# GD32F20x_CL register map
File version: 1.0
CPU: CM3 r2p1, little endian, no MPU, no FPU, 4 interrupt priority bits
Registers are 32-bit, read-write, reset 0x0 unless marked. A register's access mark holds for its fields unless they carry their own. Offsets are from the block's base; [hi:lo] are bit positions; {n}, {i} and the like mark numbered series.

## SDIO — Secure digital input/output interface
Base 0x40018000
0x00 PWRCTL — Power control register
  [1:0] PWRCTL
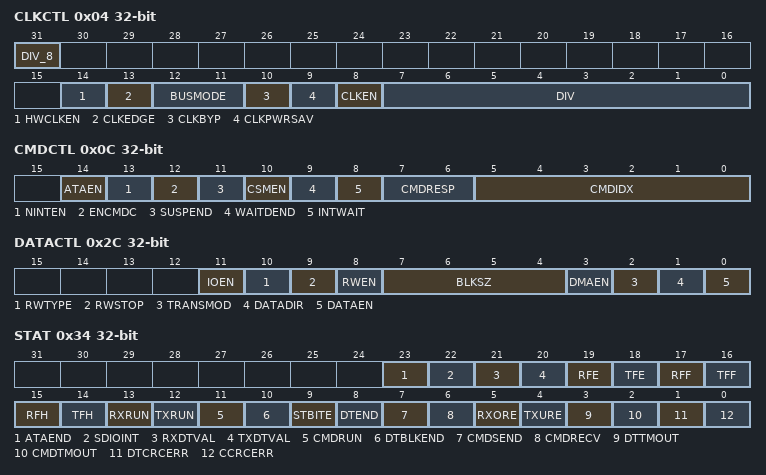
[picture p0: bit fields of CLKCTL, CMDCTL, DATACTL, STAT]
0x04 CLKCTL — SDI clock control register (SDIO_CLKCTL)
  [31] DIV_8 — MSB of Clock Division
  [14] HWCLKEN — Hardware Clock Control enable bit
  [13] CLKEDGE — SDIO_CLK clock edge selection bit
  [12:11] BUSMODE — SDIO card bus mode control bit
  [10] CLKBYP — Clock divider bypass enable bit
  [9] CLKPWRSAV — SDIO_CLK clock dynamic switch on/off for power saving
  [8] CLKEN — Clock enable bit
  [7:0] DIV — Clock divide factor
0x08 CMDAGMT — Command argument register
  [31:0] CMDAGMT — SDIO card command argument
0x0C CMDCTL — Command control register
  [14] ATAEN — CE-ATA command enable(CE-ATA only)
  [13] NINTEN — No CE-ATA Interrupt (CE-ATA only)
  [12] ENCMDC — CMD completion signal enabled (CE-ATA only)
  [11] SUSPEND — SD I/O suspend command(SD I/O only)
  [10] CSMEN — Command state machine (CSM) enable bit
  [9] WAITDEND — Waits for ends of data transfer
  [8] INTWAIT — Interrupt wait instead of timeout
  [7:6] CMDRESP — Command response type bits
  [5:0] CMDIDX — Command index
0x10 RSPCMDIDX ro — Command index response register
  [5:0] RSPCMDIDX — Last response command index
{0x14+4i} RESP{i} ro (i=0..3) — Response register {i}
  [31:0] RESP{i} — Card state
0x24 DATATO — Data timeout register
  [31:0] DATATO — Data timeout period
0x28 DATALEN — Data length register
  [24:0] DATALEN — Data transfer length
0x2C DATACTL — Data control register
  [11] IOEN — SD I/O specific function enable(SD I/O only)
  [10] RWTYPE — Read wait type(SD I/O only)
  [9] RWSTOP — Read wait stop(SD I/O only)
  [8] RWEN — Read wait mode enabled(SD I/O only)
  [7:4] BLKSZ — Data block size
  [3] DMAEN — DMA enable bit
  [2] TRANSMOD — Data transfer mode
  [1] DATADIR — Data transfer direction
  [0] DATAEN — Data transfer enable bit
0x30 DATACNT ro — Data counter register
  [24:0] DATACNT — Data count value
0x34 STAT ro — SDIO status register (SDIO_STR)
  [23] ATAEND — CE-ATA command completion signal received (only for CMD61)
  [22] SDIOINT — SD I/O interrupt received
  [21] RXDTVAL — Data is valid in receive FIFO
  [20] TXDTVAL — Data is valid in transmit FIFO
  [19] RFE — Receive FIFO is empty
  [18] TFE — Transmit FIFO is empty
  [17] RFF — Receive FIFO is full
  [16] TFF — Transmit FIFO is full
  [15] RFH — Receive FIFO is half full: at least 8 words can be read in the FIFO
  [14] TFH — Transmit FIFO is half empty: at least 8 words can be written into the FIFO
  [13] RXRUN — Data reception in progress
  [12] TXRUN — Data transmission in progress
  [11] CMDRUN — Command transmission in progress
  [10] DTBLKEND — Data block sent/received (CRC check passed)
  [9] STBITE — Start bit error in the bus
  [8] DTEND — Data end (data counter, SDIO_DATACNT, is zero)
  [7] CMDSEND — Command sent (no response required)
  [6] CMDRECV — Command response received (CRC check passed)
  [5] RXORE — Received FIFO overrun error occurs
  [4] TXURE — Transmit FIFO underrun error occurs
  [3] DTTMOUT — Data timeout
  [2] CMDTMOUT — Command response timeout
  [1] DTCRCERR — Data block sent/received (CRC check failed)
  [0] CCRCERR — Command response received (CRC check failed)
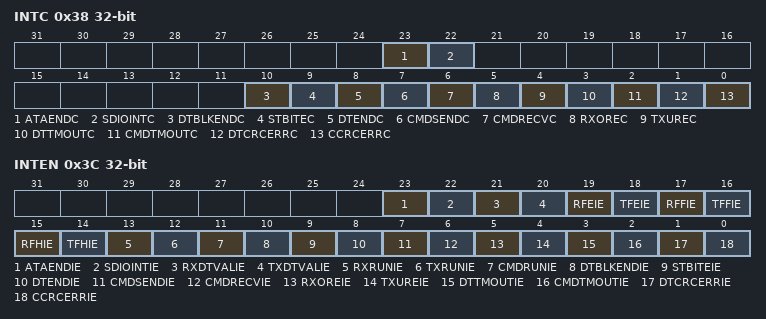
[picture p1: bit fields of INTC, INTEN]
0x38 INTC wo — Interrupt clear register (SDIO_INTC)
  [23] ATAENDC — ATAEND flag clear bit
  [22] SDIOINTC — SDIOINT flag clear bit
  [10] DTBLKENDC — DTBLKEND flag clear bit
  [9] STBITEC — STBITE flag clear bit
  [8] DTENDC — DTEND flag clear bit
  [7] CMDSENDC — CMDSEND flag clear bit
  [6] CMDRECVC — CMDRECV flag clear bit
  [5] RXOREC — RXORE flag clear bit
  [4] TXUREC — TXURE flag clear bit
  [3] DTTMOUTC — DTTMOUT flag clear bit
  [2] CMDTMOUTC — CMDTMOUT flag clear bit
  [1] DTCRCERRC — DTCRCERR flag clear bit
  [0] CCRCERRC — CCRCERR flag clear bit
0x3C INTEN — Interrupt Enable register
  [23] ATAENDIE — CE-ATA command completion signal received interrupt enable
  [22] SDIOINTIE — SD I/O interrupt received interrupt enable
  [21] RXDTVALIE — Data valid in receive FIFO interrupt enable
  [20] TXDTVALIE — Data valid in transmit FIFO interrupt enable
  [19] RFEIE — Receive FIFO empty interrupt enable
  [18] TFEIE — Transmit FIFO empty interrupt enable
  [17] RFFIE — Receive FIFO full interrupt enable
  [16] TFFIE — Transmit FIFO full interrupt enable
  [15] RFHIE — Receive FIFO half full interrupt enable
  [14] TFHIE — Transmit FIFO half empty interrupt enable
  [13] RXRUNIE — Data reception interrupt enable
  [12] TXRUNIE — Data transmission interrupt enable
  [11] CMDRUNIE — Command transmission interrupt enable
  [10] DTBLKENDIE — Data block end interrupt enable
  [9] STBITEIE — Start bit error interrupt enable
  [8] DTENDIE — Data end interrupt enable
  [7] CMDSENDIE — Command sent interrupt enable
  [6] CMDRECVIE — Command response received interrupt enable
  [5] RXOREIE — Received FIFO overrun error interrupt enable
  [4] TXUREIE — Transmit FIFO underrun error interrupt enable
  [3] DTTMOUTIE — Data timeout interrupt enable
  [2] CMDTMOUTIE — Command response timeout interrupt enable
  [1] DTCRCERRIE — Data CRC fail interrupt enable
  [0] CCRCERRIE — Command response CRC fail interrupt enable
0x48 FIFOCNT ro — FIFO counter register
  [23:0] FIFOCNT — FIFO counter
0x80 FIFO — FIFO data register
  [31:0] FIFODT — Receive FIFO data or transmit FIFO data
